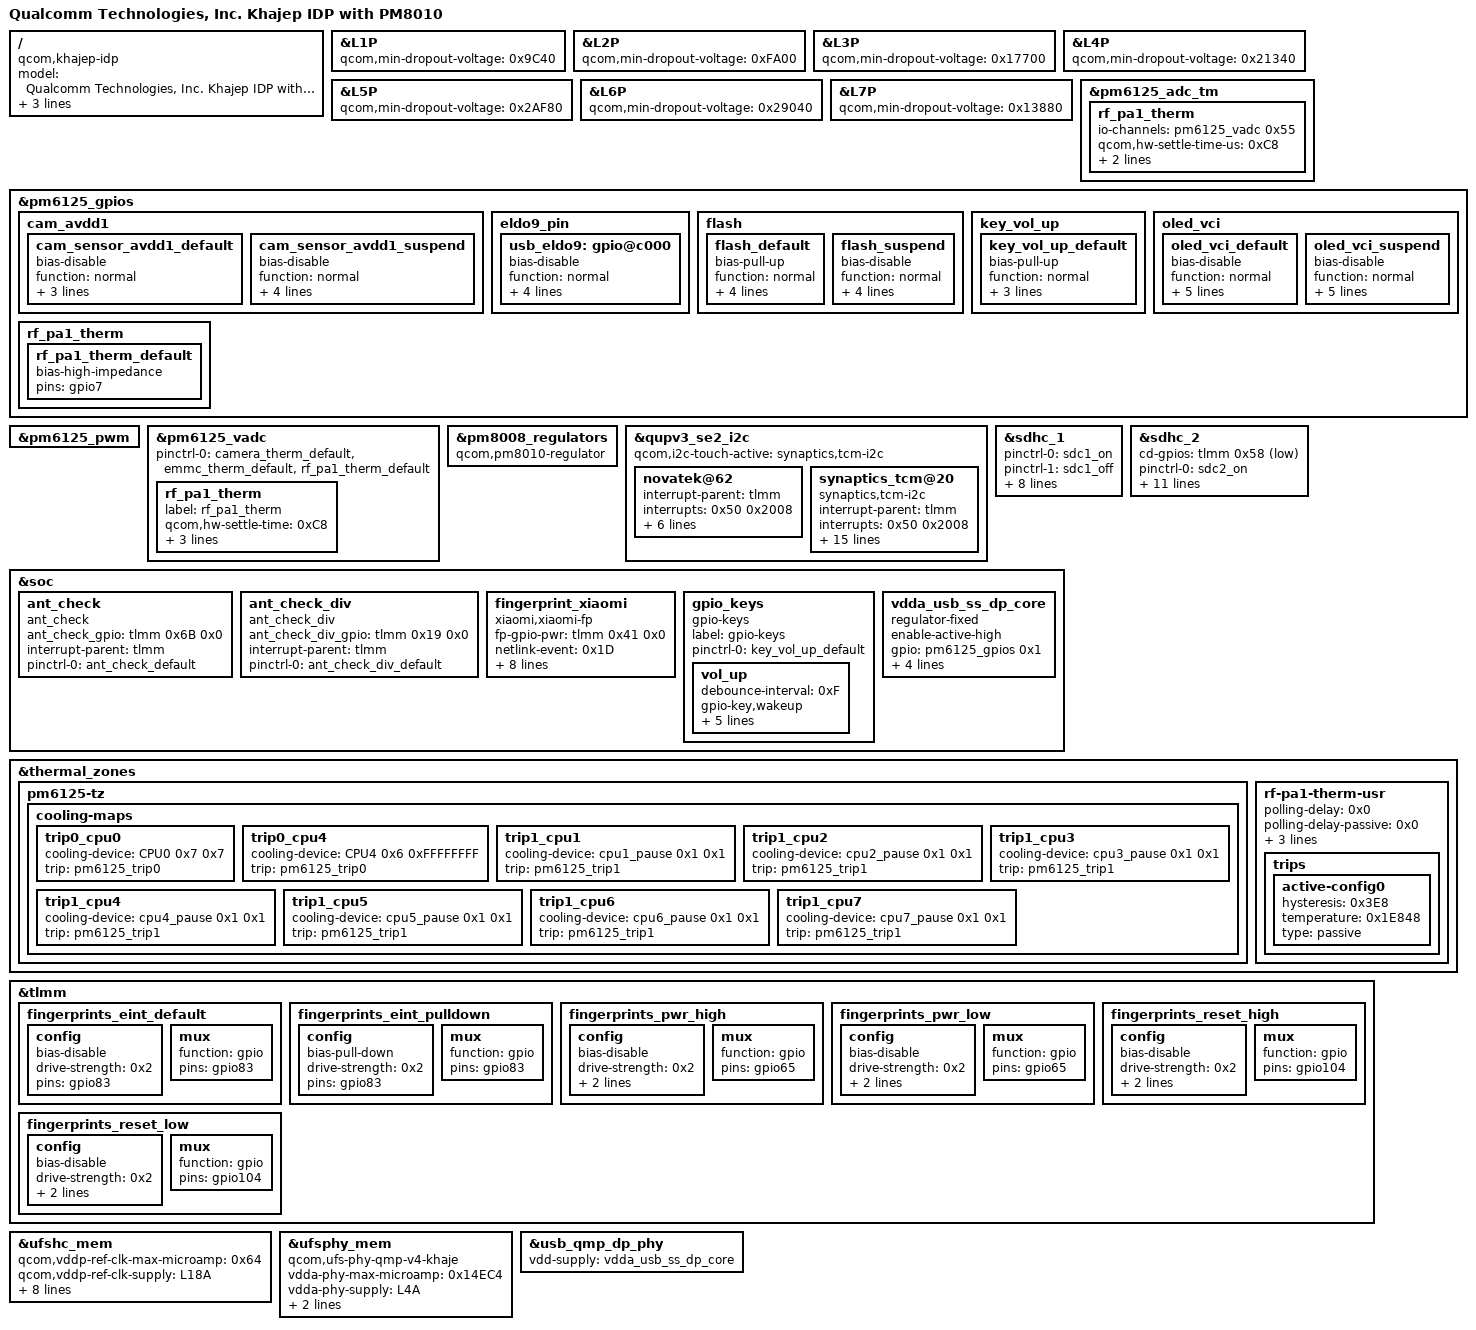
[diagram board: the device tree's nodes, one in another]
/dts-v1/;

/ {
    compatible = "qcom,khajep-idp", "qcom,khajep", "qcom,idp";
    model = "Qualcomm Technologies, Inc. Khajep IDP with PM8010";
    qcom,board-id = <0x10222 0x0>;
    qcom,msm-id = <0x231 0x10000>;
    qcom,pmic-id = <0x2D 0x2E 0x0 0x0>;
};

&L1P {
    qcom,min-dropout-voltage = <0x9C40>;
};

&L2P {
    qcom,min-dropout-voltage = <0xFA00>;
};

&L3P {
    qcom,min-dropout-voltage = <0x17700>;
};

&L4P {
    qcom,min-dropout-voltage = <0x21340>;
};

&L5P {
    qcom,min-dropout-voltage = <0x2AF80>;
};

&L6P {
    qcom,min-dropout-voltage = <0x29040>;
};

&L7P {
    qcom,min-dropout-voltage = <0x13880>;
};

&pm6125_adc_tm {
    status = "ok";
    rf_pa1_therm {
        io-channels = <&pm6125_vadc 0x55>;
        qcom,hw-settle-time-us = <0xC8>;
        qcom,ratiometric;
        reg = <0x3>;
    };
};

&pm6125_gpios {
    cam_avdd1 {
        cam_sensor_avdd1_default: cam_sensor_avdd1_default {
            bias-disable;
            function = "normal";
            pins = "gpio2";
            power-source = <0x0>;
            qcom,drive-strength = <0x2>;
        };
        cam_sensor_avdd1_suspend: cam_sensor_avdd1_suspend {
            bias-disable;
            function = "normal";
            output-low;
            pins = "gpio2";
            power-source = <0x0>;
            qcom,drive-strength = <0x2>;
        };
    };
    eldo9_pin {
        usb_eldo9: gpio@c000 {
            bias-disable;
            function = "normal";
            output-high;
            pins = "gpio1";
            power-source = <0x0>;
            qcom,drive-strength = <0x2>;
        };
    };
    flash {
        flash_default: flash_default {
            bias-pull-up;
            function = "normal";
            output-high;
            pins = "gpio8";
            power-source = <0x1>;
            qcom,drive-strength = <0x2>;
        };
        flash_suspend: flash_suspend {
            bias-disable;
            function = "normal";
            output-low;
            pins = "gpio8";
            power-source = <0x1>;
            qcom,drive-strength = <0x2>;
        };
    };
    key_vol_up {
        key_vol_up_default: key_vol_up_default {
            bias-pull-up;
            function = "normal";
            input-enable;
            pins = "gpio5";
            power-source = <0x0>;
        };
    };
    oled_vci {
        oled_vci_default: oled_vci_default {
            bias-disable;
            function = "normal";
            input-disable;
            output-high;
            pins = "gpio9";
            power-source = <0x0>;
            qcom,drive-strength = <0x2>;
        };
        oled_vci_suspend: oled_vci_suspend {
            bias-disable;
            function = "normal";
            input-disable;
            output-low;
            pins = "gpio9";
            power-source = <0x0>;
            qcom,drive-strength = <0x2>;
        };
    };
    rf_pa1_therm {
        rf_pa1_therm_default: rf_pa1_therm_default {
            bias-high-impedance;
            pins = "gpio7";
        };
    };
};

&pm6125_pwm {
    status = "ok";
};

&pm6125_vadc {
    pinctrl-0 = <&camera_therm_default &emmc_therm_default &rf_pa1_therm_default>;
    rf_pa1_therm {
        label = "rf_pa1_therm";
        qcom,hw-settle-time = <0xC8>;
        qcom,pre-scaling = <0x1 0x1>;
        qcom,ratiometric;
        reg = <0x55>;
    };
};

&pm8008_regulators {
    compatible = "qcom,pm8010-regulator";
};

&qupv3_se2_i2c {
    qcom,i2c-touch-active = "synaptics,tcm-i2c";
    status = "okay";
    novatek@62 {
        interrupt-parent = <&tlmm>;
        interrupts = <0x50 0x2008>;
        novatek,irq-gpio = <&tlmm 0x50 0x2008>;
        novatek,reset-gpio = <&tlmm 0x56 0x0>;
        pinctrl-0 = <&ts_int_active &ts_reset_active>;
        pinctrl-1 = <&ts_int_suspend &ts_reset_suspend>;
        pinctrl-2 = <&ts_release>;
        pinctrl-names = "pmx_ts_active", "pmx_ts_suspend", "pmx_ts_release";
        reg = <0x62>;
        status = "ok";
    };
    synaptics_tcm@20 {
        compatible = "synaptics,tcm-i2c";
        interrupt-parent = <&tlmm>;
        interrupts = <0x50 0x2008>;
        pinctrl-0 = <&ts_int_active &ts_reset_active>;
        pinctrl-1 = <&ts_int_suspend &ts_reset_suspend>;
        pinctrl-2 = <&ts_release>;
        pinctrl-names = "pmx_ts_active", "pmx_ts_suspend", "pmx_ts_release";
        reg = <0x20>;
        synaptics,extend_report;
        synaptics,firmware-name = "synaptics_firmware_k.img";
        synaptics,irq-gpio = <&tlmm 0x50 0x2008>;
        synaptics,irq-on-state = <0x0>;
        synaptics,power-delay-ms = <0xC8>;
        synaptics,reset-active-ms = <0x14>;
        synaptics,reset-delay-ms = <0xC8>;
        synaptics,reset-gpio = <&tlmm 0x56 0x0>;
        synaptics,reset-on-state = <0x0>;
        synaptics,ubl-i2c-addr = <0x20>;
    };
};

&sdhc_1 {
    pinctrl-0 = <&sdc1_on>;
    pinctrl-1 = <&sdc1_off>;
    pinctrl-names = "default", "sleep";
    qcom,vdd-current-level = <0x0 0x8B290>;
    qcom,vdd-io-always-on;
    qcom,vdd-io-current-level = <0x0 0x4F588>;
    qcom,vdd-io-lpm-sup;
    qcom,vdd-io-voltage-level = <0x1B7740 0x1B7740>;
    qcom,vdd-voltage-level = <0x2D2A80 0x2D2A80>;
    status = "ok";
    vdd-io-supply = <&L11A>;
    vdd-supply = <&L24A>;
};

&sdhc_2 {
    cd-gpios = <&tlmm 0x58 0x1>;
    pinctrl-0 = <&sdc2_on>;
    pinctrl-1 = <&sdc2_off>;
    pinctrl-names = "default", "sleep";
    qcom,vdd-current-level = <0x0 0xC3500>;
    qcom,vdd-io-bias-current-level = <0x0 0x1770>;
    qcom,vdd-io-bias-voltage-level = <0x132A40 0x132A40>;
    qcom,vdd-io-current-level = <0x0 0x55F0>;
    qcom,vdd-io-voltage-level = <0x1B7740 0x2D2A80>;
    qcom,vdd-voltage-level = <0x2D2A80 0x2D2A80>;
    status = "ok";
    vdd-io-bias-supply = <&L7A>;
    vdd-io-supply = <&L5A>;
    vdd-supply = <&L22A>;
};

&soc {
    ant_check {
        ant_check_gpio = <&tlmm 0x6B 0x0>;
        compatible = "ant_check";
        interrupt-parent = <&tlmm>;
        pinctrl-0 = <&ant_check_default>;
        pinctrl-names = "default";
    };
    ant_check_div {
        ant_check_div_gpio = <&tlmm 0x19 0x0>;
        compatible = "ant_check_div";
        interrupt-parent = <&tlmm>;
        pinctrl-0 = <&ant_check_div_default>;
        pinctrl-names = "default";
    };
    fingerprint_xiaomi {
        compatible = "xiaomi,xiaomi-fp";
        fp-gpio-pwr = <&tlmm 0x41 0x0>;
        netlink-event = <0x1D>;
        pinctrl-0 = <&fingerprints_reset_high>;
        pinctrl-1 = <&fingerprints_reset_low>;
        pinctrl-2 = <&fingerprints_eint_default>;
        pinctrl-3 = <&fingerprints_eint_pulldown>;
        pinctrl-4 = <&fingerprints_pwr_high>;
        pinctrl-5 = <&fingerprints_pwr_low>;
        pinctrl-names = "reset_high", "reset_low", "eint_default", "eint_pulldown", "pwr_high", "pwr_low";
        status = "okay";
        vfp-supply = <&pm6125_l9>;
        xiaomi,gpio_irq = <&tlmm 0x53 0x0>;
    };
    gpio_keys {
        compatible = "gpio-keys";
        label = "gpio-keys";
        pinctrl-0 = <&key_vol_up_default>;
        pinctrl-names = "default";
        vol_up {
            debounce-interval = <0xF>;
            gpio-key,wakeup;
            gpios = <&pm6125_gpios 0x5 0x1>;
            label = "volume_up";
            linux,can-disable;
            linux,code = <0x73>;
            linux,input-type = <0x1>;
        };
    };
    vdda_usb_ss_dp_core {
        compatible = "regulator-fixed";
        enable-active-high;
        gpio = <&pm6125_gpios 0x1 0x0>;
        pinctrl-0 = <&usb_eldo9>;
        pinctrl-names = "default";
        regulator-max-microvolt = <0xD6D80>;
        regulator-min-microvolt = <0xD6D80>;
        regulator-name = "vdd_supply";
    };
};

&thermal_zones {
    pm6125-tz {
        cooling-maps {
            trip0_cpu0 {
                cooling-device = <&CPU0 0x7 0x7>;
                trip = <&pm6125_trip0>;
            };
            trip0_cpu4 {
                cooling-device = <&CPU4 0x6 0xFFFFFFFF>;
                trip = <&pm6125_trip0>;
            };
            trip1_cpu1 {
                cooling-device = <&cpu1_pause 0x1 0x1>;
                trip = <&pm6125_trip1>;
            };
            trip1_cpu2 {
                cooling-device = <&cpu2_pause 0x1 0x1>;
                trip = <&pm6125_trip1>;
            };
            trip1_cpu3 {
                cooling-device = <&cpu3_pause 0x1 0x1>;
                trip = <&pm6125_trip1>;
            };
            trip1_cpu4 {
                cooling-device = <&cpu4_pause 0x1 0x1>;
                trip = <&pm6125_trip1>;
            };
            trip1_cpu5 {
                cooling-device = <&cpu5_pause 0x1 0x1>;
                trip = <&pm6125_trip1>;
            };
            trip1_cpu6 {
                cooling-device = <&cpu6_pause 0x1 0x1>;
                trip = <&pm6125_trip1>;
            };
            trip1_cpu7 {
                cooling-device = <&cpu7_pause 0x1 0x1>;
                trip = <&pm6125_trip1>;
            };
        };
    };
    rf-pa1-therm-usr {
        polling-delay = <0x0>;
        polling-delay-passive = <0x0>;
        thermal-governor = "user_space";
        thermal-sensors = <&pm6125_adc_tm 0x3>;
        wake-capable-sensor;
        trips {
            active-config0 {
                hysteresis = <0x3E8>;
                temperature = <0x1E848>;
                type = "passive";
            };
        };
    };
};

&tlmm {
    fingerprints_eint_default: fingerprints_eint_default {
        config {
            bias-disable;
            drive-strength = <0x2>;
            pins = "gpio83";
        };
        mux {
            function = "gpio";
            pins = "gpio83";
        };
    };
    fingerprints_eint_pulldown: fingerprints_eint_pulldown {
        config {
            bias-pull-down;
            drive-strength = <0x2>;
            pins = "gpio83";
        };
        mux {
            function = "gpio";
            pins = "gpio83";
        };
    };
    fingerprints_pwr_high: fingerprints_pwr_high {
        config {
            bias-disable;
            drive-strength = <0x2>;
            output-high;
            pins = "gpio65";
        };
        mux {
            function = "gpio";
            pins = "gpio65";
        };
    };
    fingerprints_pwr_low: fingerprints_pwr_low {
        config {
            bias-disable;
            drive-strength = <0x2>;
            output-high;
            pins = "gpio65";
        };
        mux {
            function = "gpio";
            pins = "gpio65";
        };
    };
    fingerprints_reset_high: fingerprints_reset_high {
        config {
            bias-disable;
            drive-strength = <0x2>;
            output-high;
            pins = "gpio104";
        };
        mux {
            function = "gpio";
            pins = "gpio104";
        };
    };
    fingerprints_reset_low: fingerprints_reset_low {
        config {
            bias-disable;
            drive-strength = <0x2>;
            output-low;
            pins = "gpio104";
        };
        mux {
            function = "gpio";
            pins = "gpio104";
        };
    };
};

&ufshc_mem {
    qcom,vddp-ref-clk-max-microamp = <0x64>;
    qcom,vddp-ref-clk-supply = <&L18A>;
    reset-gpios = <&tlmm 0x71 0x1>;
    reset-names = "rst";
    resets = <&gcc 0x4>;
    status = "ok";
    vcc-max-microamp = "\f5";
    vcc-supply = <&L24A>;
    vccq2-max-microamp = "\f5";
    vccq2-supply = <&L11A>;
    vdd-hba-fixed-regulator;
    vdd-hba-supply = <&gcc_ufs_phy_gdsc>;
};

&ufsphy_mem {
    compatible = "qcom,ufs-phy-qmp-v4-khaje";
    status = "ok";
    vdda-phy-max-microamp = <0x14EC4>;
    vdda-phy-supply = <&L4A>;
    vdda-pll-max-microamp = <0x477C>;
    vdda-pll-supply = <&L18A>;
};

&usb_qmp_dp_phy {
    vdd-supply = <&vdda_usb_ss_dp_core>;
};

